# KM1M7CF13 register map
Vendor: Nuvoton Technology Corporation Japan; Series: KM1M7CF; File version: 1.0.3
CPU: CM7 r1p2, little endian, MPU, FPU, double-precision FPU, I-cache, D-cache, ITCM, DTCM, 4 interrupt priority bits
Registers are 32-bit, read-write, no defined reset value unless marked. A register's access mark holds for its fields unless they carry their own. Offsets are from the block's base; [hi:lo] are bit positions; {n}, {i} and the like mark numbered series.

## NF — Noise Filter
Base 0x40100100
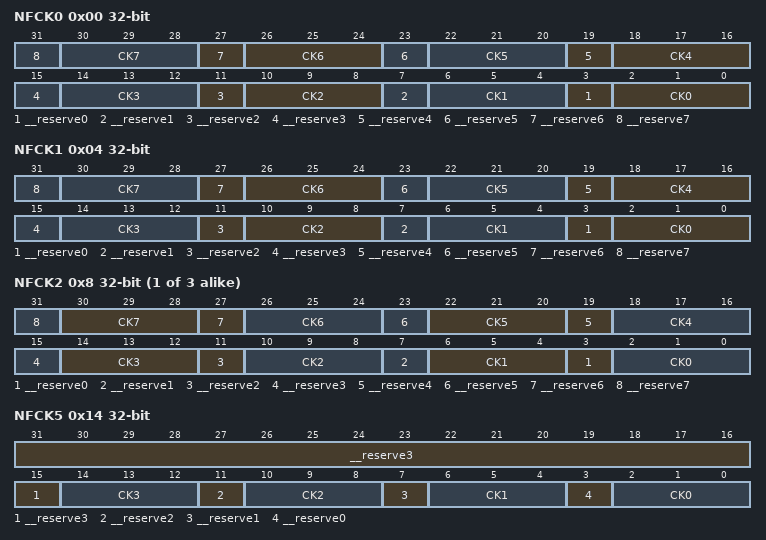
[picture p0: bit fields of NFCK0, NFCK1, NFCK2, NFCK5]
0x00 NFCK0 access per field — Sampling Clock Setting Register 0
  [4n+3] __reserve{n} ro (n=0..7) — "0" is always read out.
  [4n+2:4n] CK{n} rw (n=0..7) — Sampling clock frequency selection for IRQ{n:02}
0x04 NFCK1 access per field — Sampling Clock Setting Register 1
  [4n+3] __reserve{n} ro (n=0..7) — "0" is always read out.
  [4n+2:4n] CK{n} rw (n=0..7) — Sampling clock frequency selection for IRQ{n+8:02}
{0x0+4i} NFCK{i} access per field (i=2..4) — Sampling Clock Setting Register {i}
  [4n+3] __reserve{n} ro (n=0..7) — "0" is always read out.
  [30:28] CK7 rw — Sampling clock frequency selection for TM{4i-5:02}B
  [26:24] CK6 rw — Sampling clock frequency selection for TM{4i-5:02}A
  [22:20] CK5 rw — Sampling clock frequency selection for TM{4i-6:02}B
  [18:16] CK4 rw — Sampling clock frequency selection for TM{4i-6:02}A
  [14:12] CK3 rw — Sampling clock frequency selection for TM{4i-7:02}B
  [10:8] CK2 rw — Sampling clock frequency selection for TM{4i-7:02}A
  [6:4] CK1 rw — Sampling clock frequency selection for TM{4i-8:02}B
  [2:0] CK0 rw — Sampling clock frequency selection for TM{4i-8:02}A
0x14 NFCK5 access per field — Sampling Clock Setting Register 5
  [31:15] __reserve3 ro — "0" is always read out.
  [14:12] CK3 rw — Sampling clock frequency selection for TM13B
  [11] __reserve2 ro — "0" is always read out.
  [10:8] CK2 rw — Sampling clock frequency selection for TM13A
  [7] __reserve1 ro — "0" is always read out.
  [6:4] CK1 rw — Sampling clock frequency selection for TM12B
  [3] __reserve0 ro — "0" is always read out.
  [2:0] CK0 rw — Sampling clock frequency selection for TM12A
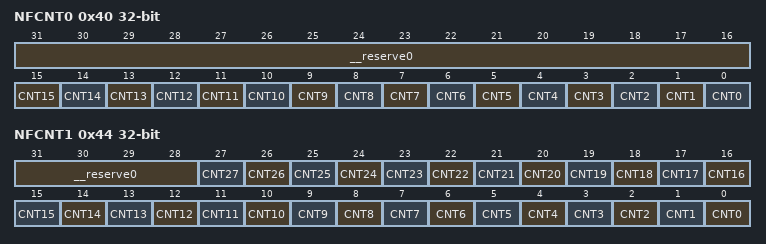
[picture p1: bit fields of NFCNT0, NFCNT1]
0x40 NFCNT0 access per field — Noise Filter Control Register 0
  [31:16] __reserve0 ro — "0" is always read out.
  [n] CNT{n} rw (n=0..15) — Noise filter enabled/disabled selection for IRQ{n}
0x44 NFCNT1 access per field — Noise Filter Control Register 1
  [31:28] __reserve0 ro — "0" is always read out.
  [27] CNT27 rw — Noise filter enabled/disabled selection for TM13B
  [26] CNT26 rw — Noise filter enabled/disabled selection for TM13A
  [25] CNT25 rw — Noise filter enabled/disabled selection for TM12B
  [24] CNT24 rw — Noise filter enabled/disabled selection for TM12A
  [23] CNT23 rw — Noise filter enabled/disabled selection for TM11B
  [22] CNT22 rw — Noise filter enabled/disabled selection for TM11A
  [21] CNT21 rw — Noise filter enabled/disabled selection for TM10B
  [20] CNT20 rw — Noise filter enabled/disabled selection for TM10A
  [19] CNT19 rw — Noise filter enabled/disabled selection for TM09B
  [18] CNT18 rw — Noise filter enabled/disabled selection for TM09A
  [17] CNT17 rw — Noise filter enabled/disabled selection for TM08B
  [16] CNT16 rw — Noise filter enabled/disabled selection for TM08A
  [15] CNT15 rw — Noise filter enabled/disabled selection for TM07B
  [14] CNT14 rw — Noise filter enabled/disabled selection for TM07A
  [13] CNT13 rw — Noise filter enabled/disabled selection for TM06B
  [12] CNT12 rw — Noise filter enabled/disabled selection for TM06A
  [11] CNT11 rw — Noise filter enabled/disabled selection for TM05B
  [10] CNT10 rw — Noise filter enabled/disabled selection for TM05A
  [9] CNT9 rw — Noise filter enabled/disabled selection for TM04B
  [8] CNT8 rw — Noise filter enabled/disabled selection for TM04A
  [7] CNT7 rw — Noise filter enabled/disabled selection for TM03B
  [6] CNT6 rw — Noise filter enabled/disabled selection for TM03A
  [5] CNT5 rw — Noise filter enabled/disabled selection for TM02B
  [4] CNT4 rw — Noise filter enabled/disabled selection for TM02A
  [3] CNT3 rw — Noise filter enabled/disabled selection for TM01B
  [2] CNT2 rw — Noise filter enabled/disabled selection for TM01A
  [1] CNT1 rw — Noise filter enabled/disabled selection for TM00B
  [0] CNT0 rw — Noise filter enabled/disabled selection for TM00A
